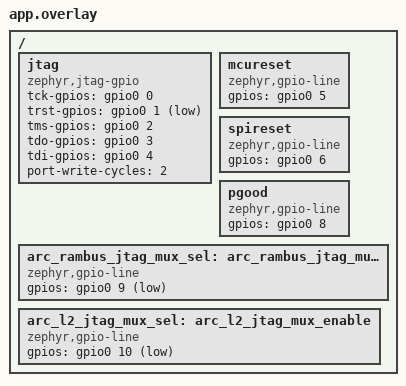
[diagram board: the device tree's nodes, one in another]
/*
 * Copyright (c) 2024 Tenstorrent AI ULC
 *
 * SPDX-License-Identifier: Apache-2.0
 */

#include <zephyr/dt-bindings/gpio/gpio.h>

/ {
	jtag {
		compatible = "zephyr,jtag-gpio";
		status = "okay";
		tck-gpios = <&gpio0 0 GPIO_ACTIVE_HIGH>;
		trst-gpios = <&gpio0 1 GPIO_ACTIVE_LOW>;
		tms-gpios = <&gpio0 2 GPIO_ACTIVE_HIGH>;
		tdo-gpios = <&gpio0 3 GPIO_PULL_UP>;
		tdi-gpios = <&gpio0 4 GPIO_ACTIVE_HIGH>;
		port-write-cycles = <2>;
	};

	/* ASIC reset line */
	mcureset {
		compatible = "zephyr,gpio-line";
		gpios = <&gpio0 5 GPIO_PULL_DOWN>;
	};

	/* Spi reset line */
	spireset {
		compatible = "zephyr,gpio-line";
		gpios = <&gpio0 6 GPIO_PULL_DOWN>;
	};

	/* Power good indicator */
	pgood {
		compatible = "zephyr,gpio-line";
		gpios = <&gpio0 8 GPIO_PULL_DOWN>;
	};

	/* Enable to select the arc jtag, disable to select rambus */
	arc_rambus_jtag_mux_sel: arc_rambus_jtag_mux_enable {
		compatible = "zephyr,gpio-line";
		gpios = <&gpio0 9 GPIO_ACTIVE_LOW>;
	};

	/* Enable to select the arc jtag, disable to select l2cpu */
	arc_l2_jtag_mux_sel: arc_l2_jtag_mux_enable {
		compatible = "zephyr,gpio-line";
		gpios = <&gpio0 10 GPIO_ACTIVE_LOW>;
	};
};
